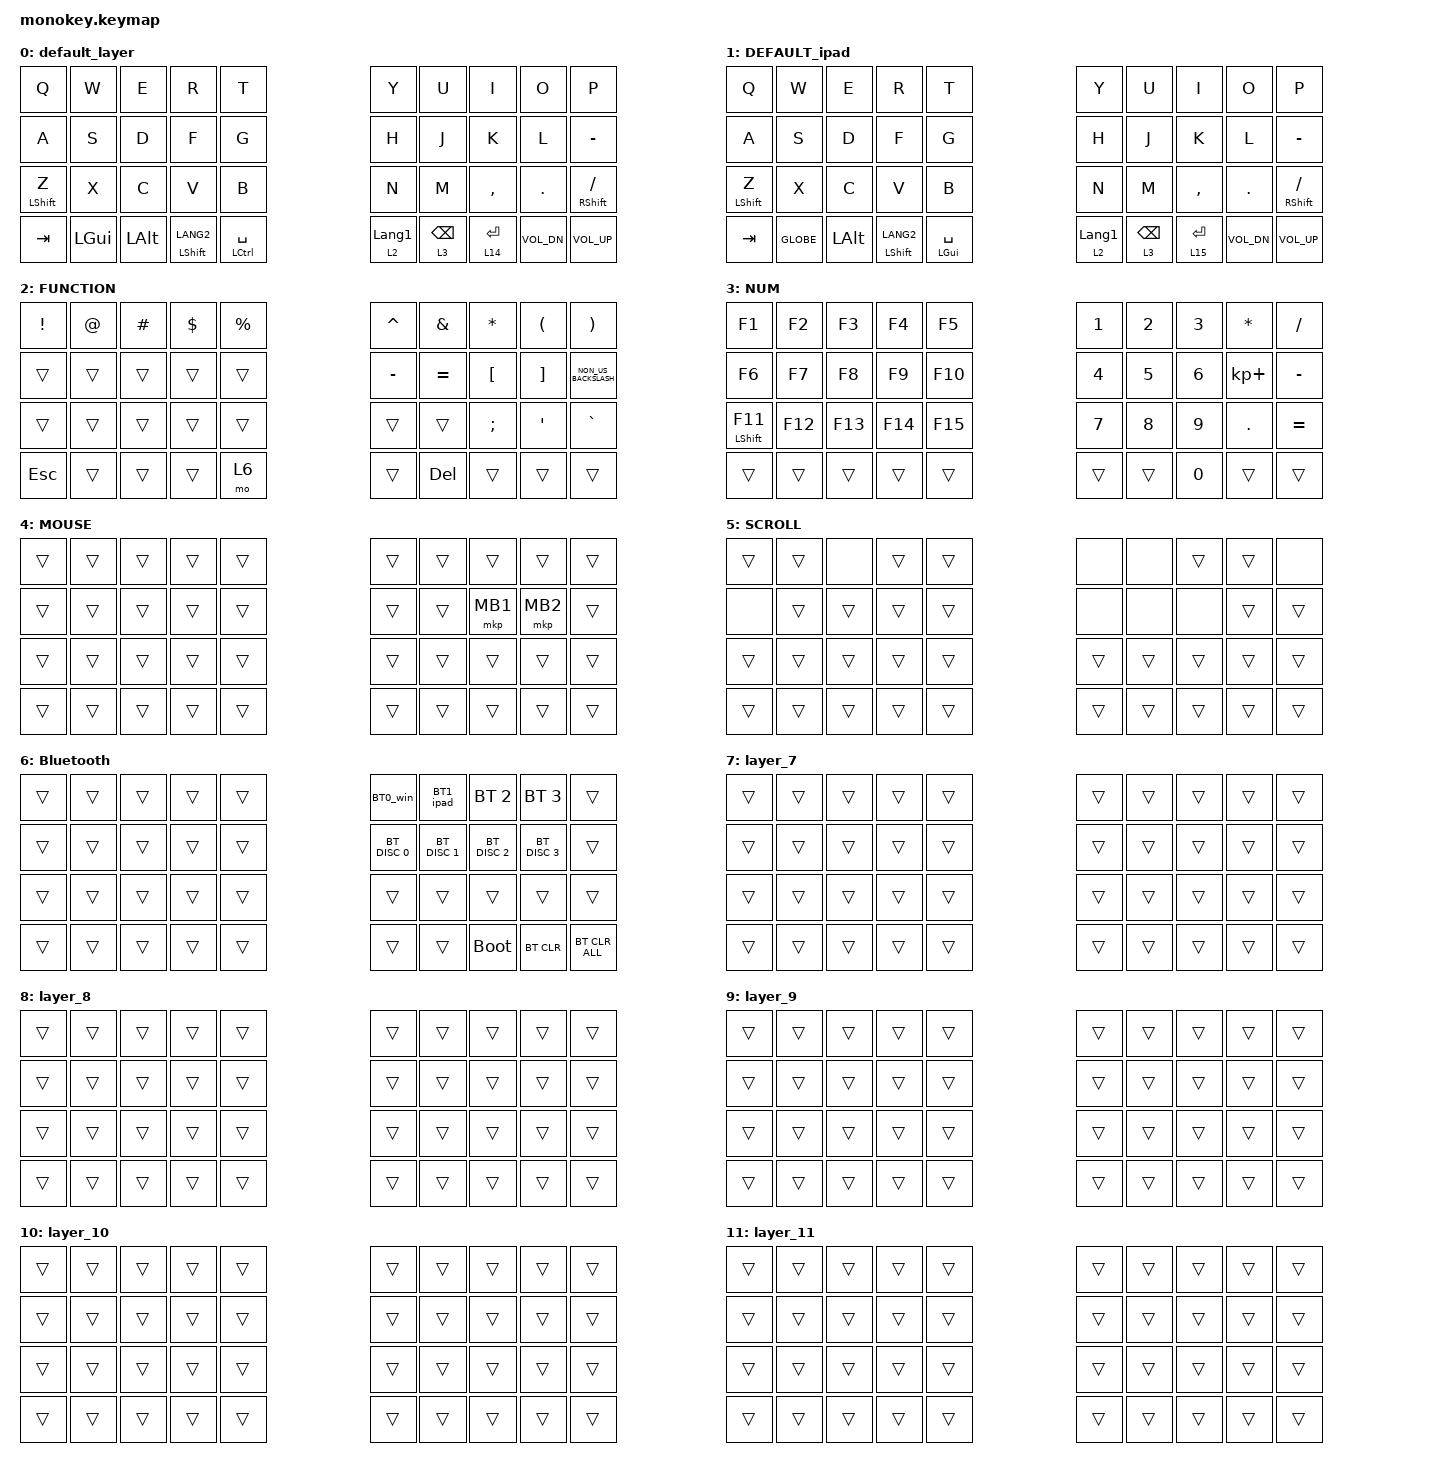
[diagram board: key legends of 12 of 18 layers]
#include <behaviors.dtsi>
#include <dt-bindings/zmk/bt.h>
#include <dt-bindings/zmk/keys.h>
#include <dt-bindings/zmk/pointing.h>

#define MOUSE 4
#define SCROLL 5
#define NUM 6

&mt {
    flavor = "balanced";
    quick-tap-ms = <300>;
};

&lt { quick-tap-ms = <300>; };

/ {
    combos {
        compatible = "zmk,combos";

        scroll {
            bindings = <&mo 5>;
            key-positions = <17 18>;
        };

        gesture {
            bindings = <&mo 13>;
            key-positions = <7 8>;
            timeout-ms = <50>;
        };

        mb3 {
            bindings = <&mkp MB3>;
            key-positions = <19 18>;
        };

    };

    behaviors {
        right_click: right_click_behavior {
            compatible = "zmk,behavior-mouse-key";
            label = "RIGHT_CLICK";
            #binding-cells = <0>;
            bindings = <&mkp MB2>;
        };

        tog_on: toggle_layer_on_only {
            compatible = "zmk,behavior-toggle-layer";
            #binding-cells = <1>;
            display-name = "Toggle Layer On";
            toggle-mode = "on";
        };

        tog_off: toggle_layer_off_only {
            compatible = "zmk,behavior-toggle-layer";
            #binding-cells = <1>;
            display-name = "Toggle Layer Off";
            toggle-mode = "off";
        };

        BT0_win: BT0_Win {
            compatible = "zmk,behavior-macro";
            #binding-cells = <0>;
            bindings =
                <&bt BT_SEL 0>,
                <&macro_wait_time 200>,
                <&to 0>;
        };

        BT1_ipad: BT1_ipad {
            compatible = "zmk,behavior-macro";
            #binding-cells = <0>;
            bindings =
                <&bt BT_SEL 1>,
                <&macro_wait_time 200>,
                <&to 1>;
        };

        ipad_appswtch: ipad_appswtch {
            compatible = "zmk,behavior-macro";
            #binding-cells = <0>;
            bindings =
                <&macro_press>,
                <&kp GLOBE>,
                <&macro_tap>,
                <&kp UP_ARROW>,
                <&macro_release>,
                <&kp GLOBE>;
        };

        ipad_home: ipad_home {
            compatible = "zmk,behavior-macro";
            #binding-cells = <0>;
            bindings =
                <&macro_press>,
                <&kp GLOBE>,
                <&macro_tap>,
                <&kp H>,
                <&macro_release>,
                <&kp GLOBE>;
        };

        ipad_cotrlcntr: ipad_cotrlcntr {
            compatible = "zmk,behavior-macro";
            #binding-cells = <0>;
            bindings =
                <&macro_press>,
                <&kp GLOBE>,
                <&macro_tap>,
                <&kp C>,
                <&macro_release>,
                <&kp GLOBE>;
        };
    };

    macros {};

    conditional_layers {
        compatible = "zmk,conditional-layers";

        win_gesture_layer {
            if-layers = <0 13>;
            then-layer = <17>;
        };

        ipad_gesture_layer {
            if-layers = <1 13>;
            then-layer = <16>;
        };
    };

    keymap {
        compatible = "zmk,keymap";

        default_layer {
            bindings = <
&kp Q             &kp W         &kp E         &kp R                 &kp T                                               &kp Y         &kp U  &kp I      &kp O         &kp P
&kp A             &kp S         &kp D         &kp F                 &kp G                                               &kp H         &kp J  &kp K      &kp L         &kp MINUS
&mt LEFT_SHIFT Z  &kp X         &kp C         &kp V                 &kp B                                               &kp N         &kp M  &kp COMMA  &kp PERIOD    &mt RIGHT_SHIFT SLASH
&kp TAB           &kp LEFT_GUI  &kp LEFT_ALT  &mt LEFT_SHIFT LANG2  &mt LCTRL SPACE  &lt 2 LANGUAGE_1  &lt 3 BACKSPACE  &lt 14 RETURN                   &kp C_VOL_DN  &kp C_VOLUME_UP
            >;

            sensor-bindings = <&inc_dec_kp PG_UP PAGE_DOWN>;
        };

        DEFAULT_ipad {
            bindings = <
&kp Q             &kp W      &kp E         &kp R                 &kp T                                                  &kp Y        &kp U  &kp I      &kp O         &kp P
&kp A             &kp S      &kp D         &kp F                 &kp G                                                  &kp H        &kp J  &kp K      &kp L         &kp MINUS
&mt LEFT_SHIFT Z  &kp X      &kp C         &kp V                 &kp B                                                  &kp N        &kp M  &kp COMMA  &kp PERIOD    &mt RIGHT_SHIFT SLASH
&kp TAB           &kp GLOBE  &kp LEFT_ALT  &mt LEFT_SHIFT LANG2  &mt LEFT_GUI SPACE  &lt 2 LANGUAGE_1  &lt 3 BACKSPACE  &lt 15 ENTER                    &kp C_VOL_DN  &kp C_VOLUME_UP
            >;

            sensor-bindings = <&inc_dec_kp PG_UP PAGE_DOWN>;
        };

        FUNCTION {
            bindings = <
&kp EXCLAMATION  &kp AT_SIGN  &kp HASH  &kp DOLLAR  &kp PERCENT                      &kp CARET  &kp AMPERSAND  &kp ASTERISK      &kp LEFT_PARENTHESIS  &kp RIGHT_PARENTHESIS
&trans           &trans       &trans    &trans      &trans                           &kp MINUS  &kp EQUAL      &kp LEFT_BRACKET  &kp RIGHT_BRACKET     &kp NON_US_BACKSLASH
&trans           &trans       &trans    &trans      &trans                           &trans     &trans         &kp SEMICOLON     &kp SINGLE_QUOTE      &kp GRAVE
&kp ESCAPE       &trans       &trans    &trans      &mo 6        &trans  &kp DELETE  &trans                                      &trans                &trans
            >;
        };

        NUM {
            bindings = <
&kp F1              &kp F2   &kp F3   &kp F4   &kp F5                   &kp NUMBER_1  &kp NUMBER_2  &kp NUMBER_3  &kp ASTRK    &kp SLASH
&kp F6              &kp F7   &kp F8   &kp F9   &kp F10                  &kp NUMBER_4  &kp N5        &kp NUMBER_6  &kp KP_PLUS  &kp MINUS
&mt LEFT_SHIFT F11  &kp F12  &kp F13  &kp F14  &kp F15                  &kp N7        &kp N8        &kp N9        &kp PERIOD   &kp EQUAL
&trans              &trans   &trans   &trans   &trans   &trans  &trans  &kp N0                                    &trans       &trans
            >;
        };

        MOUSE {
            bindings = <
&trans  &trans  &trans  &trans  &trans                  &trans  &trans  &trans    &trans    &trans
&trans  &trans  &trans  &trans  &trans                  &trans  &trans  &mkp MB1  &mkp MB2  &trans
&trans  &trans  &trans  &trans  &trans                  &trans  &trans  &trans    &trans    &trans
&trans  &trans  &trans  &trans  &trans  &trans  &trans  &trans                    &trans    &trans
            >;
        };

        SCROLL {
            bindings = <
&trans  &trans  &none   &trans  &trans                  &none   &none   &trans  &trans  &none
&none   &trans  &trans  &trans  &trans                  &none   &none   &none   &trans  &trans
&trans  &trans  &trans  &trans  &trans                  &trans  &trans  &trans  &trans  &trans
&trans  &trans  &trans  &trans  &trans  &trans  &trans  &trans                  &trans  &trans
            >;
        };

        Bluetooth {
            bindings = <
&trans  &trans  &trans  &trans  &trans                  &BT0_win       &BT1_ipad      &bt BT_SEL 2   &bt BT_SEL 3   &trans
&trans  &trans  &trans  &trans  &trans                  &bt BT_DISC 0  &bt BT_DISC 1  &bt BT_DISC 2  &bt BT_DISC 3  &trans
&trans  &trans  &trans  &trans  &trans                  &trans         &trans         &trans         &trans         &trans
&trans  &trans  &trans  &trans  &trans  &trans  &trans  &bootloader                                  &bt BT_CLR     &bt BT_CLR_ALL
            >;
        };

        layer_7 {
            bindings = <
&trans  &trans  &trans  &trans  &trans                  &trans  &trans  &trans  &trans  &trans
&trans  &trans  &trans  &trans  &trans                  &trans  &trans  &trans  &trans  &trans
&trans  &trans  &trans  &trans  &trans                  &trans  &trans  &trans  &trans  &trans
&trans  &trans  &trans  &trans  &trans  &trans  &trans  &trans                  &trans  &trans
            >;
        };

        layer_8 {
            bindings = <
&trans  &trans  &trans  &trans  &trans                  &trans  &trans  &trans  &trans  &trans
&trans  &trans  &trans  &trans  &trans                  &trans  &trans  &trans  &trans  &trans
&trans  &trans  &trans  &trans  &trans                  &trans  &trans  &trans  &trans  &trans
&trans  &trans  &trans  &trans  &trans  &trans  &trans  &trans                  &trans  &trans
            >;
        };

        layer_9 {
            bindings = <
&trans  &trans  &trans  &trans  &trans                  &trans  &trans  &trans  &trans  &trans
&trans  &trans  &trans  &trans  &trans                  &trans  &trans  &trans  &trans  &trans
&trans  &trans  &trans  &trans  &trans                  &trans  &trans  &trans  &trans  &trans
&trans  &trans  &trans  &trans  &trans  &trans  &trans  &trans                  &trans  &trans
            >;
        };

        layer_10 {
            bindings = <
&trans  &trans  &trans  &trans  &trans                  &trans  &trans  &trans  &trans  &trans
&trans  &trans  &trans  &trans  &trans                  &trans  &trans  &trans  &trans  &trans
&trans  &trans  &trans  &trans  &trans                  &trans  &trans  &trans  &trans  &trans
&trans  &trans  &trans  &trans  &trans  &trans  &trans  &trans                  &trans  &trans
            >;
        };

        layer_11 {
            bindings = <
&trans  &trans  &trans  &trans  &trans                  &trans  &trans  &trans  &trans  &trans
&trans  &trans  &trans  &trans  &trans                  &trans  &trans  &trans  &trans  &trans
&trans  &trans  &trans  &trans  &trans                  &trans  &trans  &trans  &trans  &trans
&trans  &trans  &trans  &trans  &trans  &trans  &trans  &trans                  &trans  &trans
            >;
        };

        precision_layer {
            bindings = <
&none  &none  &none  &none  &none    &none  &none  &none  &none  &none
&none  &none  &none  &none  &none    &none  &none  &mkp MB1  &mkp MB2  &mkp MB3
&none  &none  &none  &none  &none    &none  &none  &none  &none  &none
&none  &none  &none  &none  &none  &none    &none  &none  &none  &tog 12
            >;
        };

        gesture_layer {
            bindings = <
&none  &none  &none  &none  &none    &none  &none  &none  &none  &none
&none  &none  &none  &none  &none    &none  &none  &none  &none  &none
&none  &none  &none  &none  &none    &none  &none  &none  &none  &none
&none  &none  &none  &none  &none  &none    &none  &none  &none  &none
            >;
        };

        ARROW_win {
            bindings = <
&trans  &trans  &kp PRINTSCREEN  &kp LS(LG(S))      &kp LA(LC(T))                  &kp LG(LS(LEFT_ARROW))  &kp LG(LEFT_ARROW)  &kp UP_ARROW    &kp LG(RIGHT)    &kp RG(RS(RIGHT))
&trans  &trans  &kp LC(LA(G))    &kp LC(LS(EQUAL))  &kp LC(EQUAL)                  &kp LA(LS(TAB))         &kp LEFT_ARROW      &kp DOWN_ARROW  &kp RIGHT_ARROW  &kp RA(RC(TAB))
&trans  &trans  &trans           &trans             &trans                         &kp LC(LS(TAB))         &mkp MB4            &kp LG(D)       &mkp MB5         &kp LC(TAB)
&trans  &trans  &trans           &trans             &trans         &trans  &trans  &trans                                      &kp C_BRI_DEC    &kp C_BRI_INC
            >;

            sensor-bindings = <&inc_dec_kp LC(PAGE_UP) LC(PAGE_DOWN)>;
        };

        ARROW_ipad {
            bindings = <
&trans  &trans  &kp LS(LG(NUMBER_3))  &kp LS(LG(NUMBER_4))  &trans                                &ipad_cotrlcntr  &kp LA(LEFT_ARROW)  &kp UP_ARROW    &kp LA(RIGHT)    &ipad_appswtch
&trans  &trans  &trans                &kp LG(LS(EQUAL))     &kp LG(EQUAL)                         &kp LG(LS(TAB))  &kp LEFT_ARROW      &kp DOWN_ARROW  &kp RIGHT_ARROW  &kp LG(TAB)
&trans  &trans  &trans                &trans                &trans                                &kp LS(LC(TAB))  &kp LG(LBKT)        &kp LG(H)       &kp LG(RBKT)     &kp LC(TAB)
&trans  &trans  &trans                &trans                &trans         &kp LG(SPACE)  &trans  &trans                                      &kp C_BRI_DEC    &kp C_BRI_INC
            >;

            sensor-bindings = <&inc_dec_kp LC(PAGE_UP) LC(PAGE_DOWN)>;
        };

        gesture_layer_ipad {
            bindings = <
&none  &none  &none  &none  &none    &none  &none  &ipad_appswtch  &none  &none
&none  &none  &none  &none  &none    &none  &kp LG(LEFT_ARROW)  &none  &kp LG(RIGHT_ARROW)  &none
&none  &none  &none  &none  &none    &none  &none  &ipad_home  &none  &none
&none  &none  &none  &none  &none  &none    &none  &none  &none  &none
            >;
        };

        gesture_layer_win {
            bindings = <
&none  &none  &none  &none  &none    &none  &none  &kp LC(DOWN)  &none  &none
&none  &none  &none  &none  &none    &none  &kp LC(RIGHT)  &none  &kp LC(LEFT)  &none
&none  &none  &none  &none  &none    &none  &none  &kp LC(UP)  &none  &none
&none  &none  &none  &none  &none  &none    &none  &none  &none  &none
            >;
        };

    };
};
